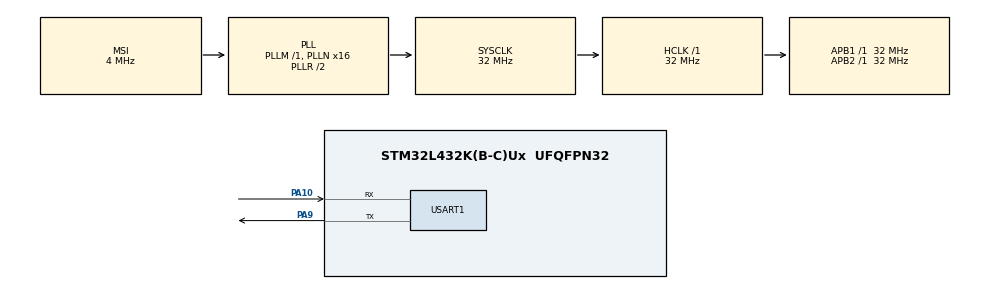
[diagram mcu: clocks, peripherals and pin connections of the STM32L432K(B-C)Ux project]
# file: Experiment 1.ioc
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FREERTOS.BinarySemaphores01=event_signal,Dynamic,NULL
FREERTOS.Mutexes01=usart_lock,Dynamic,NULL
FREERTOS.Queues01=queueRQ,4,uint16_t,0,Dynamic,NULL,NULL;queueSQ,1,uint16_t,0,Dynamic,NULL,NULL
FREERTOS.Tasks01=defaultTask,24,128,StartDefaultTask,Default,NULL,Dynamic,NULL,NULL;Task1_Evaluate,24,128,StartTask02,Default,NULL,Dynamic,NULL,NULL;Task2_UARTSend,24,128,StartTask03,Default,NULL,Dynamic,NULL,NULL;Task3_UARTRecei,24,128,StartTask04,Default,NULL,Dynamic,NULL,NULL
Mcu.Family=STM32L4
Mcu.Name=STM32L432K(B-C)Ux
Mcu.Package=UFQFPN32
NVIC.PriorityGroup=NVIC_PRIORITYGROUP_4
NVIC.TIM1_UP_TIM16_IRQn=true\:0\:0\:false\:false\:true\:false\:false\:true
NVIC.TimeBase=TIM1_UP_TIM16_IRQn
NVIC.TimeBaseIP=TIM1
NVIC.USART1_IRQn=true\:5\:0\:false\:false\:true\:true\:true\:true
PA10.Mode=Asynchronous
PA10.Signal=USART1_RX
PA13\ (JTMS-SWDIO).Mode=Serial_Wire
PA13\ (JTMS-SWDIO).Signal=SYS_JTMS-SWDIO
PA14\ (JTCK-SWCLK).Mode=Serial_Wire
PA14\ (JTCK-SWCLK).Signal=SYS_JTCK-SWCLK
PA9.Mode=Asynchronous
PA9.Signal=USART1_TX
PC14-OSC32_IN\ (PC14).Mode=LSE-External-Oscillator
PC14-OSC32_IN\ (PC14).Signal=RCC_OSC32_IN
PC15-OSC32_OUT\ (PC15).Mode=LSE-External-Oscillator
PC15-OSC32_OUT\ (PC15).Signal=RCC_OSC32_OUT
ProjectManager.HeapSize=0x200
ProjectManager.StackSize=0x400
ProjectManager.TargetToolchain=MDK-ARM V5.27
RCC.ADCFreq_Value=16000000
RCC.AHBFreq_Value=32000000
RCC.APB1Freq_Value=32000000
RCC.APB1TimFreq_Value=32000000
RCC.APB2Freq_Value=32000000
RCC.APB2TimFreq_Value=32000000
RCC.CortexFreq_Value=32000000
RCC.HCLKFreq_Value=32000000
RCC.HSE_VALUE=8000000
RCC.HSI48_VALUE=48000000
RCC.HSI_VALUE=16000000
RCC.MSI_VALUE=4000000
RCC.PLLN=16
RCC.SYSCLKFreq_VALUE=32000000
RCC.SYSCLKSource=RCC_SYSCLKSOURCE_PLLCLK
RCC.USBFreq_Value=16000000
RCC.VCOOutputFreq_Value=64000000
USART1.VirtualMode-Asynchronous=VM_ASYNC
VP_FREERTOS_VS_CMSIS_V2.Mode=CMSIS_V2
VP_SYS_VS_tim1.Mode=TIM1
board=custom

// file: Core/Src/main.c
/* USER CODE BEGIN Header */
/**
  ******************************************************************************
  * @file           : main.c
  * @brief          : Main program body
  ******************************************************************************
  * @attention
  *
  * <h2><center>&copy; Copyright (c) 2021 STMicroelectronics.
  * All rights reserved.</center></h2>
  *
  * This software component is licensed by ST under Ultimate Liberty license
  * SLA0044, the "License"; You may not use this file except in compliance with
  * the License. You may obtain a copy of the License at:
  *                             www.st.com/SLA0044
  *
  ******************************************************************************
  */
/* USER CODE END Header */
#include "main.h"
#include "cmsis_os.h"
#include "queue.h"
#include "semphr.h"

UART_HandleTypeDef huart1;
SemaphoreHandle_t event_signal;

//QueueHandle_t queueRQ=0;
//QueueHandle_t queueSQ=0;
uint8_t my_char;
/* Definitions for defaultTask */
osThreadId_t defaultTaskHandle;
const osThreadAttr_t defaultTask_attributes = {
  .name = "defaultTask",
  .priority = (osPriority_t) osPriorityNormal,
  .stack_size = 128 * 4
};
/* Definitions for Task1_Evaluate */
osThreadId_t Task1_EvaluateHandle;
const osThreadAttr_t Task1_Evaluate_attributes = {
  .name = "Task1_Evaluate",
  .priority = (osPriority_t) osPriorityNormal,
  .stack_size = 128 * 4
};
/* Definitions for Task2_UARTSend */
osThreadId_t Task2_UARTSendHandle;
const osThreadAttr_t Task2_UARTSend_attributes = {
  .name = "Task2_UARTSend",
  .priority = (osPriority_t) osPriorityNormal,
  .stack_size = 128 * 4
};
/* Definitions for Task3_UARTRecei */
osThreadId_t Task3_UARTReceiHandle;
const osThreadAttr_t Task3_UARTRecei_attributes = {
  .name = "Task3_UARTRecei",
  .priority = (osPriority_t) osPriorityNormal,
  .stack_size = 128 * 4
};
/* Definitions for queueRQ */
osMessageQueueId_t queueRQHandle;
const osMessageQueueAttr_t queueRQ_attributes = {
  .name = "queueRQ"
};
/* Definitions for queueSQ */
osMessageQueueId_t queueSQHandle;
const osMessageQueueAttr_t queueSQ_attributes = {
  .name = "queueSQ"
};
/* Definitions for usart_lock */
osMutexId_t usart_lockHandle;
const osMutexAttr_t usart_lock_attributes = {
  .name = "usart_lock"
};
/* Definitions for event_signal */
osSemaphoreId_t event_signalHandle;
const osSemaphoreAttr_t event_signal_attributes = {
  .name = "event_signal"
};

void SystemClock_Config(void);
static void MX_GPIO_Init(void);
static void MX_USART1_UART_Init(void);
void StartDefaultTask(void *argument);
void StartTask02(void *argument);
void StartTask03(void *argument);
void StartTask04(void *argument);

int main(void)
{

  /* MCU Configuration--------------------------------------------------------*/

  /* Reset of all peripherals, Initializes the Flash interface and the Systick. */
  HAL_Init();

  /* Configure the system clock */
  SystemClock_Config();

  /* Initialize all configured peripherals */
  MX_GPIO_Init();
  MX_USART1_UART_Init();

  /* Init scheduler */
  osKernelInitialize();
  /* Create the mutex(es) */
  /* creation of usart_lock */
  usart_lockHandle = osMutexNew(&usart_lock_attributes);

  /* Create the semaphores(s) */
  /* creation of event_signal */
  event_signalHandle = osSemaphoreNew(1, 1, &event_signal_attributes);

  /* Create the queue(s) */
  /* creation of queueRQ */
  queueRQHandle = osMessageQueueNew (4, sizeof(uint16_t), &queueRQ_attributes);

  /* creation of queueSQ */
  queueSQHandle = osMessageQueueNew (1, sizeof(uint16_t), &queueSQ_attributes);

  /* Create the thread(s) */
  /* creation of defaultTask */
  defaultTaskHandle = osThreadNew(StartDefaultTask, NULL, &defaultTask_attributes);

  /* creation of Task1_Evaluate */
  Task1_EvaluateHandle = osThreadNew(StartTask02, NULL, &Task1_Evaluate_attributes);

  /* creation of Task2_UARTSend */
  Task2_UARTSendHandle = osThreadNew(StartTask03, NULL, &Task2_UARTSend_attributes);

  /* creation of Task3_UARTRecei */
  Task3_UARTReceiHandle = osThreadNew(StartTask04, NULL, &Task3_UARTRecei_attributes);

  /* Start scheduler */
//	HAL_UART_Receive(&huart1, &my_char, 1, HAL_MAX_DELAY);
//	xQueueSendToBackFromISR(queueRQ, &my_char, NULL);
//	uint8_t my_char_receive;
//	xQueueReceiveFromISR(queueRQ, &my_char_receive, NULL);
//	HAL_UART_Transmit(&huart1, &my_char_receive, 4, HAL_MAX_DELAY);
vSemaphoreCreateBinary( event_signal ); // Create the semaphore
	//xSemaphoreTake(event_signal, 0); // Take semaphore after creating it.
__HAL_UART_ENABLE_IT(&huart1,UART_IT_RXNE);
  osKernelStart();

  /* We should never get here as control is now taken by the scheduler */
  /* Infinite loop */
  while (1)
  {

  }
}

void SystemClock_Config(void)
{
  RCC_OscInitTypeDef RCC_OscInitStruct = {0};
  RCC_ClkInitTypeDef RCC_ClkInitStruct = {0};
  RCC_PeriphCLKInitTypeDef PeriphClkInit = {0};

  /** Configure LSE Drive Capability
  */
  HAL_PWR_EnableBkUpAccess();
  __HAL_RCC_LSEDRIVE_CONFIG(RCC_LSEDRIVE_LOW);
  /** Initializes the RCC Oscillators according to the specified parameters
  * in the RCC_OscInitTypeDef structure.
  */
  RCC_OscInitStruct.OscillatorType = RCC_OSCILLATORTYPE_LSE|RCC_OSCILLATORTYPE_MSI;
  RCC_OscInitStruct.LSEState = RCC_LSE_ON;
  RCC_OscInitStruct.MSIState = RCC_MSI_ON;
  RCC_OscInitStruct.MSICalibrationValue = 0;
  RCC_OscInitStruct.MSIClockRange = RCC_MSIRANGE_6;
  RCC_OscInitStruct.PLL.PLLState = RCC_PLL_ON;
  RCC_OscInitStruct.PLL.PLLSource = RCC_PLLSOURCE_MSI;
  RCC_OscInitStruct.PLL.PLLM = 1;
  RCC_OscInitStruct.PLL.PLLN = 16;
  RCC_OscInitStruct.PLL.PLLP = RCC_PLLP_DIV7;
  RCC_OscInitStruct.PLL.PLLQ = RCC_PLLQ_DIV2;
  RCC_OscInitStruct.PLL.PLLR = RCC_PLLR_DIV2;
  if (HAL_RCC_OscConfig(&RCC_OscInitStruct) != HAL_OK)
  {
    Error_Handler();
  }
  /** Initializes the CPU, AHB and APB buses clocks
  */
  RCC_ClkInitStruct.ClockType = RCC_CLOCKTYPE_HCLK|RCC_CLOCKTYPE_SYSCLK
                              |RCC_CLOCKTYPE_PCLK1|RCC_CLOCKTYPE_PCLK2;
  RCC_ClkInitStruct.SYSCLKSource = RCC_SYSCLKSOURCE_PLLCLK;
  RCC_ClkInitStruct.AHBCLKDivider = RCC_SYSCLK_DIV1;
  RCC_ClkInitStruct.APB1CLKDivider = RCC_HCLK_DIV1;
  RCC_ClkInitStruct.APB2CLKDivider = RCC_HCLK_DIV1;

  if (HAL_RCC_ClockConfig(&RCC_ClkInitStruct, FLASH_LATENCY_1) != HAL_OK)
  {
    Error_Handler();
  }
  PeriphClkInit.PeriphClockSelection = RCC_PERIPHCLK_USART1;
  PeriphClkInit.Usart1ClockSelection = RCC_USART1CLKSOURCE_PCLK2;
  if (HAL_RCCEx_PeriphCLKConfig(&PeriphClkInit) != HAL_OK)
  {
    Error_Handler();
  }
  /** Configure the main internal regulator output voltage
  */
  if (HAL_PWREx_ControlVoltageScaling(PWR_REGULATOR_VOLTAGE_SCALE1) != HAL_OK)
  {
    Error_Handler();
  }
  /** Enable MSI Auto calibration
  */
  HAL_RCCEx_EnableMSIPLLMode();
}

static void MX_USART1_UART_Init(void)
{

  huart1.Instance = USART1;
  huart1.Init.BaudRate = 115200;
  huart1.Init.WordLength = UART_WORDLENGTH_8B;
  huart1.Init.StopBits = UART_STOPBITS_1;
  huart1.Init.Parity = UART_PARITY_NONE;
  huart1.Init.Mode = UART_MODE_TX_RX;
  huart1.Init.HwFlowCtl = UART_HWCONTROL_NONE;
  huart1.Init.OverSampling = UART_OVERSAMPLING_16;
  huart1.Init.OneBitSampling = UART_ONE_BIT_SAMPLE_DISABLE;
  huart1.AdvancedInit.AdvFeatureInit = UART_ADVFEATURE_NO_INIT;
  if (HAL_UART_Init(&huart1) != HAL_OK)
  {
    Error_Handler();
  }

}

static void MX_GPIO_Init(void)
{

  /* GPIO Ports Clock Enable */
  __HAL_RCC_GPIOC_CLK_ENABLE();
  __HAL_RCC_GPIOA_CLK_ENABLE();

}

void StartDefaultTask(void *argument)
{
  for(;;)
  {
    osDelay(1);
  }
}

void StartTask02(void *argument)
{
//  /* USER CODE BEGIN StartTask02 */
	UBaseType_t temp;
	int first_num;
	int sec_num;
	int res;
	uint8_t my_char_receive;
//  /* Infinite loop */
  for(;;)
  {

		if(uxQueueSpacesAvailable(queueRQHandle)==0){
			xQueueReceive(queueRQHandle, &my_char_receive, NULL);
			first_num = my_char_receive - '0';
			xQueueReceive(queueRQHandle, &my_char_receive, NULL);
			if(my_char_receive== '+'){
				xQueueReceive(queueRQHandle, &my_char_receive, NULL);
				sec_num = my_char_receive - '0';
				res = first_num + sec_num;
			}else{
				if(my_char_receive== '-'){
					xQueueReceive(queueRQHandle, &my_char_receive, NULL);
					sec_num = my_char_receive - '0';
					res = first_num - sec_num;
				}
			}
			xQueueReceive(queueRQHandle, &my_char_receive, NULL);
			my_char_receive = res+ '0';
			xQueueSend(queueSQHandle, &my_char_receive, NULL);
//			taskENTER_CRITICAL();
//			HAL_UART_Transmit(&huart1, &my_char_receive, 1, HAL_MAX_DELAY);
//			taskEXIT_CRITICAL();
		}
//		uint8_t my_char_receive;
//		xQueueReceive(queueRQ, &my_char_receive, NULL);
//		taskENTER_CRITICAL();
//
//		HAL_UART_Transmit(&huart1, &my_char_receive, 1, HAL_MAX_DELAY);
//
//		taskEXIT_CRITICAL();
    osDelay(1);
  }
//  /* USER CODE END StartTask02 */
}

void StartTask03(void *argument)
{
  /* USER CODE BEGIN StartTask03 */
	uint8_t my_char_receive;
	uint8_t new_line;
	uint8_t carriage_return;
	carriage_return = 13;
	new_line = 10;

  /* Infinite loop */
  for(;;)
  {
		if(uxQueueSpacesAvailable(queueSQHandle)==0){
			xQueueReceive(queueSQHandle, &my_char_receive, NULL);
			taskENTER_CRITICAL();
			HAL_UART_Transmit(&huart1, &my_char_receive, 1, HAL_MAX_DELAY);
			HAL_UART_Transmit(&huart1, &carriage_return, 1, HAL_MAX_DELAY);
			HAL_UART_Transmit(&huart1, &new_line, 1, HAL_MAX_DELAY);
			taskEXIT_CRITICAL();
		}
    osDelay(1);
  }
  /* USER CODE END StartTask03 */
}

void StartTask04(void *argument)
{
  /* USER CODE BEGIN StartTask04 */
	int temp;
	uint8_t my_char;
  /* Infinite loop */
  for(;;)
  {
		if(xSemaphoreTake(event_signal, 9999999)) {
			temp=taskENTER_CRITICAL_FROM_ISR();
			HAL_UART_Receive(&huart1, &my_char, 1, HAL_MAX_DELAY);
			taskEXIT_CRITICAL_FROM_ISR(temp);
			xQueueSendFromISR(queueRQHandle, &my_char, NULL);
			//xSemaphoreGive(event_signal);
		}
    osDelay(1);
  }
  /* USER CODE END StartTask04 */
}

 /**
  * @brief  Period elapsed callback in non blocking mode
  * @note   This function is called  when TIM1 interrupt took place, inside
  * HAL_TIM_IRQHandler(). It makes a direct call to HAL_IncTick() to increment
  * a global variable "uwTick" used as application time base.
  * @param  htim : TIM handle
  * @retval None
  */
void HAL_TIM_PeriodElapsedCallback(TIM_HandleTypeDef *htim)
{
  if (htim->Instance == TIM1) {
    HAL_IncTick();
  }
}

void Error_Handler(void)
{
  __disable_irq();
  while (1)
  {
  }
}

/************************ (C) COPYRIGHT STMicroelectronics *****END OF FILE****/
